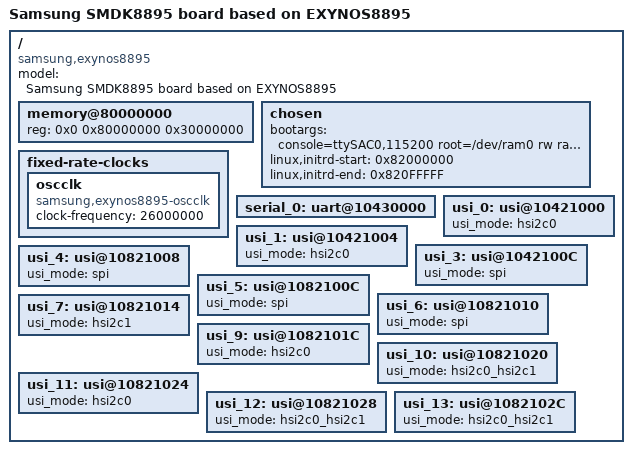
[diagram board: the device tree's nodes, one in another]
/*
 * SAMSUNG EXYNOS8895 board device tree source
 *
 * Copyright (c) 2016 Samsung Electronics Co., Ltd.
 *		http://www.samsung.com
 *
 * This program is free software; you can redistribute it and/or modify
 * it under the terms of the GNU General Public License version 2 as
 * published by the Free Software Foundation.
*/

/dts-v1/;
#include "exynos8895.dtsi"
#include "exynos8895-rmem.dtsi"

/ {
	model = "Samsung SMDK8895 board based on EXYNOS8895";
	compatible = "samsung,exynos8895", "samsung,SMDK8895";

	memory@80000000 {
		device_type = "memory";

		reg = <0x0 0x80000000 0x30000000>;
	};

	chosen {
		bootargs = "console=ttySAC0,115200 root=/dev/ram0 rw ramdisk=8192 initrd=0x82000000,8M init=/linuxrc mem=768M clk_ignore_unused";
		linux,initrd-start = <0x82000000>;
		linux,initrd-end = <0x820FFFFF>;
	};

	fixed-rate-clocks {
		oscclk {
			compatible = "samsung,exynos8895-oscclk";
			clock-frequency = <26000000>;
		};
	};

	serial_0: uart@10430000 {
		status = "okay";
	};

	usi_0: usi@10421000 {
		usi_mode = "hsi2c0";
		status = "okay";
	};

	usi_1: usi@10421004 {
		usi_mode = "hsi2c0";
		status = "okay";
	};

	usi_3: usi@1042100C {
		usi_mode = "spi";
		status = "okay";
	};

	usi_4: usi@10821008 {
		usi_mode = "spi";
		status = "okay";
	};

	usi_5: usi@1082100C {
		usi_mode = "spi";
		status = "okay";
	};

	usi_6: usi@10821010 {
		usi_mode = "spi";
		status = "okay";
	};

	usi_7: usi@10821014 {
		usi_mode = "hsi2c1";
		status = "okay";
	};

	usi_9: usi@1082101C {
		usi_mode = "hsi2c0";
		status = "okay";
	};

	usi_10: usi@10821020 {
		usi_mode = "hsi2c0_hsi2c1";
		status = "okay";
	};

	usi_11: usi@10821024 {
		usi_mode = "hsi2c0";
		status = "okay";
	};

	usi_12: usi@10821028 {
		usi_mode = "hsi2c0_hsi2c1";
		status = "okay";
	};

	usi_13: usi@1082102C {
		usi_mode = "hsi2c0_hsi2c1";
		status = "okay";
	};
};
